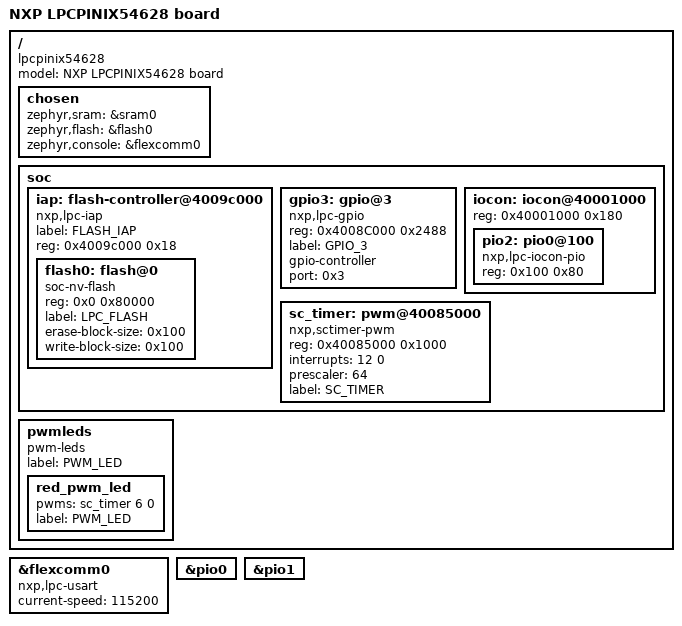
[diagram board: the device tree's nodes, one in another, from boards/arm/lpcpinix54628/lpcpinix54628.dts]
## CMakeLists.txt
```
# SPDX-License-Identifier: Apache-2.0

cmake_minimum_required(VERSION 3.16.0)

#set(ENV{ZEPHYR_TOOLCHAIN_VARIANT} gnuarmemb)

find_package(Zephyr REQUIRED HINTS $ENV{ZEPHYR_BASE})
project(blinky)

zephyr_library_link_libraries(/home/kkoroke/study/lpc-pinix-54628/libpower_hardabi.a)
target_sources(app PRIVATE src/main.c src/clock.c)
```

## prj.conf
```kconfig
CONFIG_GPIO=y
CONFIG_FPU=y
CONFIG_FP_HARDABI=y
CONFIG_LED=y
CONFIG_PWM=y
CONFIG_LED_PWM=y
```

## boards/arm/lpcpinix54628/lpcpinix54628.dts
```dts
/*
 * Copyright (c) 2020 Seagate Technology LLC
 *
 * SPDX-License-Identifier: Apache-2.0
 */

/dts-v1/;

#include <nxp/nxp_lpc54xxx_m4.dtsi>

/ {
	model = "NXP LPCPINIX54628 board";
	compatible = "lpcpinix54628", "nxp,lpc";
	chosen {
		zephyr,sram = &sram0;
		zephyr,flash = &flash0;
		zephyr,console = &flexcomm0;
	};

	soc {
		
		iap: flash-controller@4009c000 {
			compatible = "nxp,lpc-iap";
			label = "FLASH_IAP";
			reg = < 0x4009c000 0x18 >;
			#address-cells = < 0x1 >;
			#size-cells = < 0x1 >;
			flash0: flash@0 {
				compatible = "soc-nv-flash";
				reg = < 0x0 0x80000 >;
				label = "LPC_FLASH";
				erase-block-size = < 0x100 >;
				write-block-size = < 0x100 >;
			};
		};
		gpio3: gpio@3 {
			compatible = "nxp,lpc-gpio";
			reg = <0x4008C000 0x2488>;

			label = "GPIO_3";
			gpio-controller;
			#gpio-cells = <2>;
			port = <0x3>;

			status = "okay";
		};

		iocon: iocon@40001000 {
			reg = < 0x40001000 0x180>;
			ranges = <0x0 0x40001000 0x180>;
			pio2: pio0@100 {
				compatible = "nxp,lpc-iocon-pio";
				reg = <0x100 0x80>;
				status = "okay";
			};
		};

		sc_timer: pwm@40085000 {
			compatible = "nxp,sctimer-pwm";
			reg = <0x40085000 0x1000>;
			interrupts = <12 0>;
			status = "okay";
			prescaler = <64>;
			label = "SC_TIMER";
			#pwm-cells = <2>;
		};
	};

	pwmleds {
		compatible = "pwm-leds";
		label = "PWM_LED";
		red_pwm_led: red_pwm_led {
			pwms = <&sc_timer 6 0>;
			label = "PWM_LED";
			status = "okay";
		};
	};

};

&flexcomm0 {
	compatible = "nxp,lpc-usart";
	current-speed = <115200>;
	status = "okay";
};

&pio0 {
	status = "okay";
};

&pio1 {
	status = "okay";
};
```

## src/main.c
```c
/*
 * Copyright (c) 2016 Intel Corporation
 *
 * SPDX-License-Identifier: Apache-2.0
 */

#include <zephyr.h>
#include <device.h>
#include <devicetree.h>
#include <drivers/gpio.h>
#include <drivers/pwm.h>
#include <sys/printk.h>


#define MIN_PERIOD_USEC	(USEC_PER_SEC / 1024U) //64Hz 
#define MAX_PERIOD_USEC	USEC_PER_SEC  //1Hz //500 msec 

#define PWM_FLAGS	DT_PWMS_FLAGS(DT_NODELABEL(red_pwm_led))

void main(void)
{
	const struct device *dev, *pwm_led;
	int ret;
	int status;
	dev = device_get_binding(DT_LABEL(DT_NODELABEL(gpio3)));
	//dev = device_get_binding(DT_GPIO_LABEL(GPIO_3,gpios));
	if(dev == NULL) {
		return;
	}

	pwm_led = device_get_binding(DT_LABEL(DT_NODELABEL(sc_timer)));
	if (!device_is_ready(pwm_led)) {
		printk("Error: PWM device %s is not ready\n", pwm_led->name);
		return;
	}

	ret = gpio_pin_configure(dev, 3, GPIO_OUTPUT_ACTIVE);
	if (ret < 0) {
		return;
	}

	gpio_pin_set(dev, 3, 0);
	status = pwm_pin_set_usec(pwm_led, 6,MAX_PERIOD_USEC, MAX_PERIOD_USEC/2, PWM_FLAGS);
	while (1) {
		printk("hello world!(%d)\n",status);
		k_msleep(20000);

		//status = pwm_pin_set_usec(pwm_led, 6,MIN_PERIOD_USEC, MIN_PERIOD_USEC/2, PWM_FLAGS);
		printk("hello world!(%d)\n",status);
		//gpio_pin_set(dev, 3, 0);
		k_msleep(20000);
	}
}
```

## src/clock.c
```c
#include <zephyr.h>
#include <device.h>
#include <devicetree.h>
#include <init.h>
#include <drivers/clock_control.h>
#include "fsl_clock.h"
#include "fsl_power.h"


#define BOARD_BOOTCLOCKPLL220M_CORE_CLOCK   220000000U    /*!< Core clock frequency:220000000Hz */

static int BOARD_BootClockPLL220M(const struct device *dev)
{
    /*!< Set up the clock sources */
    /*!< Set up FRO */
    POWER_DisablePD(kPDRUNCFG_PD_FRO_EN);                   /*!< Ensure FRO is on  */
    CLOCK_AttachClk(kFRO12M_to_MAIN_CLK);                  /*!< Switch to FRO 12MHz first to ensure we can change voltage without accidentally
                                                                being below the voltage for current speed */
    POWER_SetVoltageForFreq(220000000U);             /*!< Set voltage for the one of the fastest clock outputs: System clock output */
    CLOCK_SetFLASHAccessCyclesForFreq(220000000U);    /*!< Set FLASH wait states for core */

    /*!< Set up SYS PLL */
    const pll_setup_t pllSetup = {
        .pllctrl =  SYSCON_SYSPLLCTRL_SELI(34U) | SYSCON_SYSPLLCTRL_SELP(31U) | SYSCON_SYSPLLCTRL_SELR(0U),
        .pllmdec = (SYSCON_SYSPLLMDEC_MDEC(13243U)),
        .pllndec = (SYSCON_SYSPLLNDEC_NDEC(1U)),
        .pllpdec = (SYSCON_SYSPLLPDEC_PDEC(98U)),
        .pllRate = 220000000U,
        .flags =  PLL_SETUPFLAG_WAITLOCK | PLL_SETUPFLAG_POWERUP
    };
    CLOCK_AttachClk(kFRO12M_to_SYS_PLL);        /*!< Set sys pll clock source*/
    CLOCK_SetPLLFreq(&pllSetup);                 /*!< Configure PLL to the desired value */
    /*!< Need to make sure ROM and OTP has power(PDRUNCFG0[17,29]= 0U) 
         before calling this API since this API is implemented in ROM code */
    CLOCK_SetupFROClocking(96000000U);              /*!< Set up high frequency FRO output to selected frequency */

    /*!< Set up dividers */
    CLOCK_SetClkDiv(kCLOCK_DivAhbClk, 1U, false);                  /*!< Reset divider counter and set divider to value 1 */
    CLOCK_SetClkDiv(kCLOCK_DivUsb0Clk, 0U, true);                  /*!< Reset USB0CLKDIV divider counter and halt it */
    CLOCK_SetClkDiv(kCLOCK_DivUsb0Clk, 2U, false);                  /*!< Set USB0CLKDIV divider to value 2 */

    /*!< Set up clock selectors - Attach clocks to the peripheries */
    CLOCK_AttachClk(kSYS_PLL_to_MAIN_CLK);                    /*!< Switch MAIN_CLK to SYS_PLL */
    CLOCK_AttachClk(kFRO_HF_to_USB0_CLK);                    /*!< Switch USB0_CLK to FRO_HF */
    CLOCK_AttachClk(kFRO12M_to_FLEXCOMM0);                    /*!< Switch FLEXCOMM0 to FRO12M */
    SYSCON->MAINCLKSELA = ((SYSCON->MAINCLKSELA & ~SYSCON_MAINCLKSELA_SEL_MASK) | SYSCON_MAINCLKSELA_SEL(0U)); /*!< Switch MAINCLKSELA to FRO12M even it is not used for MAINCLKSELB */
	return 0;
}


SYS_INIT(BOARD_BootClockPLL220M, PRE_KERNEL_1, 10);
```
